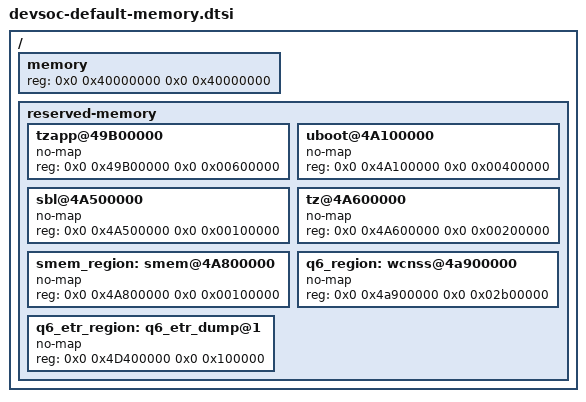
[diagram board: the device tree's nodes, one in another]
// SPDX-License-Identifier: (GPL-2.0+ OR BSD-3-Clause)
/*
 * Dev SoC Memory device tree source
 *
 * Copyright (c) 2022 Qualcomm Innovation Center, Inc. All rights reserved.
 */

/ {

	/*		  Default Profile
	 * +=========+==============+========================+
	 * |        |              |                         |
	 * | Region | Start Offset |          Size           |
	 * |        |              |                         |
	 * +--------+--------------+-------------------------+
	 * |        |              |                         |
	 * |        |              |                         |
	 * |        |              |                         |
	 * |        |              |                         |
	 * | Linux  |  0x40000000  |           161MB         |
	 * |        |              |                         |
	 * |        |              |                         |
	 * |        |              |                         |
	 * +--------+--------------+-------------------------+
	 * |        |              |                         |
	 * |        |              |                         |
	 * | TZ App |  0x49B00000  |           6MB           |
	 * |        |              |                         |
	 * |        |              |                         |
	 * +--------+--------------+-------------------------+
	 * |        |              |                         |
	 * | uboot  |  0x4A100000  |           4MB           |
	 * |        |              |                         |
	 * +--------+--------------+-------------------------+
	 * |  SBL   |  0x4A500000  |           1MB           |
	 * +--------+--------------+-------------------------+
	 * |        |              |                         |
	 * |  TZ    |  0x4A600000  |           2MB           |
	 * |        |              |                         |
	 * +--------+--------------+-------------------------+
	 * |  smem  |  0x4A800000  |           1MB           |
	 * +--------+--------------+-------------------------+
	 * |        |              |                         |
	 * |        |              |                         |
	 * | WLAN   |              |                         |
	 * |   Q6   |  0x4A900000  |          43MB           |
	 * |        |              |                         |
	 * |        |              |                         |
	 * +--------+--------------+-------------------------+
	 * | WLAN   |              |                         |
	 * | Q6 ETR |  0x4D400000  |          1MB            |
	 * | Region |              |                         |
	 * +=================================================+
	 * |                                                 |
	 * |                                                 |
	 * |                                                 |
	 * |            Rest of memory for Linux             |
	 * |                                                 |
	 * |                                                 |
	 * |                                                 |
	 * +=================================================+
	 */

	memory {
		device_type = "memory";
		reg = <0x0 0x40000000 0x0 0x40000000>;
	};

	reserved-memory {
		#address-cells = <2>;
		#size-cells = <2>;
		ranges;

		tzapp@49B00000 {
			no-map;
			reg = <0x0 0x49B00000 0x0 0x00600000>;
		};

		uboot@4A100000 {
			no-map;
			reg = <0x0 0x4A100000 0x0 0x00400000>;
		};

		sbl@4A500000 {
			no-map;
			reg = <0x0 0x4A500000 0x0 0x00100000>;
		};

		tz@4A600000 {
			no-map;
			reg = <0x0 0x4A600000 0x0 0x00200000>;
		};

		smem_region: smem@4A800000 {
			no-map;
			reg = <0x0 0x4A800000 0x0 0x00100000>;
		};

		q6_region: wcnss@4a900000 {
			no-map;
			reg = <0x0 0x4a900000 0x0 0x02b00000>;
		};

		q6_etr_region: q6_etr_dump@1 {
			no-map;
			reg = <0x0 0x4D400000 0x0 0x100000>;
		};
	};
};
